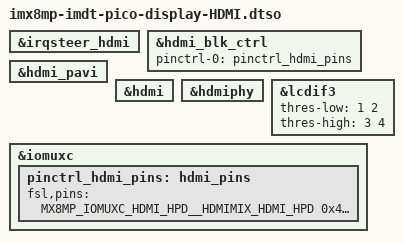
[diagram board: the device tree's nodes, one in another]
// SPDX-License-Identifier: (GPL-2.0+ OR MIT)
/*
 * Copyright 2025 IMD Technologies
 */

/dts-v1/;
/plugin/;

#include "imx8mp-pinfunc.h"

&irqsteer_hdmi {
	status = "okay";
};

&hdmi_blk_ctrl {
	pinctrl-names = "default";
	pinctrl-0 = <&pinctrl_hdmi_pins>;

	status = "okay";
};

&hdmi_pavi {
	status = "okay";
};

&hdmi {
	status = "okay";
};

&hdmiphy {
	status = "okay";
};

&lcdif3 {
	status = "okay";
	thres-low  = <1 2>;             /* (FIFO * 1 / 2) */
	thres-high = <3 4>;             /* (FIFO * 3 / 4) */
};

&iomuxc {

	pinctrl_hdmi_pins: hdmi_pins {
		fsl,pins = <
			MX8MP_IOMUXC_HDMI_HPD__HDMIMIX_HDMI_HPD		0x40000019
			MX8MP_IOMUXC_HDMI_CEC__HDMIMIX_HDMI_CEC		0x40000019
		>;
	};
};

